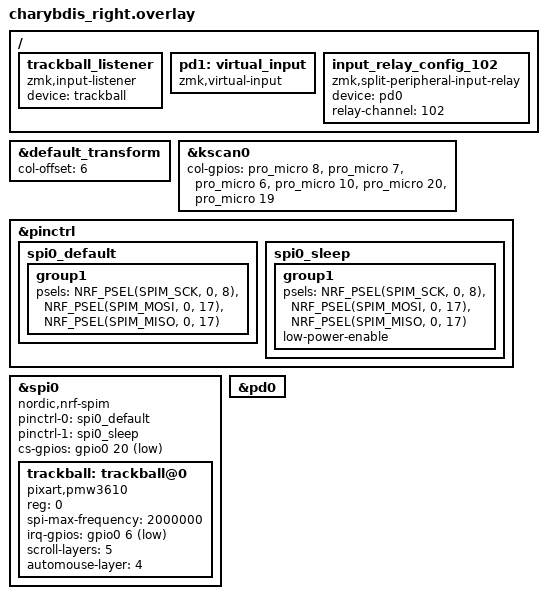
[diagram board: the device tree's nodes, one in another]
/*
 * Copyright (c) 2020 Ryan Cross
 *
 * SPDX-License-Identifier: MIT
 */

#include "charybdis.dtsi"

#define INPUT_EV_KEY 0x01               /**< Key event */
#define INPUT_EV_REL 0x02               /**< Relative coordinate event */
#define INPUT_EV_ABS 0x03               /**< Absolute coordinate event */
#define INPUT_EV_MSC 0x04               /**< Miscellaneous event */
#define INPUT_EV_VENDOR_START 0xf0      /**< Vendor specific event start */
#define INPUT_EV_VENDOR_STOP 0xff       /**< Vendor specific event stop */

#define INPUT_REL_X 0x00                /**< Relative X coordinate */
#define INPUT_REL_Y 0x01                /**< Relative Y coordinate */
#define INPUT_REL_WHEEL 0x08            /**< Relative wheel coordinate */
#define INPUT_REL_HWHEEL 0x06           /**< Relative horizontal wheel coordinate */
#define INPUT_REL_MISC 0x09             /**< Relative misc coordinate */

&default_transform {
    col-offset = <6>;
};

&kscan0 {
    col-gpios
        = <&pro_micro 8 (GPIO_ACTIVE_HIGH | GPIO_PULL_DOWN)>
        , <&pro_micro 7 (GPIO_ACTIVE_HIGH | GPIO_PULL_DOWN)>
        , <&pro_micro 6 (GPIO_ACTIVE_HIGH | GPIO_PULL_DOWN)>
        , <&pro_micro 10 (GPIO_ACTIVE_HIGH | GPIO_PULL_DOWN)>
        , <&pro_micro 20 (GPIO_ACTIVE_HIGH | GPIO_PULL_DOWN)>
        , <&pro_micro 19 (GPIO_ACTIVE_HIGH | GPIO_PULL_DOWN)>
        ;
};

&pinctrl {
    spi0_default: spi0_default {
        group1 {
            psels = <NRF_PSEL(SPIM_SCK, 0, 8)>,
                <NRF_PSEL(SPIM_MOSI, 0, 17)>,
                <NRF_PSEL(SPIM_MISO, 0, 17)>;
        };
    };

    spi0_sleep: spi0_sleep {
        group1 {
            psels = <NRF_PSEL(SPIM_SCK, 0, 8)>,
                <NRF_PSEL(SPIM_MOSI, 0, 17)>,
                <NRF_PSEL(SPIM_MISO, 0, 17)>;
            low-power-enable;
        };
    };
};

&spi0 {
    status = "okay";
    compatible = "nordic,nrf-spim";
    pinctrl-0 = <&spi0_default>;
    pinctrl-1 = <&spi0_sleep>;
    pinctrl-names = "default", "sleep";
    cs-gpios = <&gpio0 20 GPIO_ACTIVE_LOW>;

    trackball: trackball@0 {
        status = "okay";
        compatible = "pixart,pmw3610";
        reg = <0>;
        spi-max-frequency = <2000000>;
        irq-gpios = <&gpio0 6 (GPIO_ACTIVE_LOW | GPIO_PULL_UP)>;

        /*   optional features   */
        // snipe-layers = <1>;
        scroll-layers = <5>;
        automouse-layer = <4>;
    };
};

/ {
  trackball_listener {
    compatible = "zmk,input-listener";
    device = <&trackball>;

  };
};

/* enable &pd0 on split peripheral. typical input device for zephyr input subsystem. */
/* NOTE 1: use the same device alias (&pd0) on central and peripheral(s) is alright. */
/* NOTE 2: input event shall be intecepted by module `zmk-split-peripheral-input-relay`. */

/* this is an alias of your actual wired input device sensor in your peripheral shield. */
/* e.g. SPI optical sensor for trackball */
&pd0 {
	status = "okay";
	/* the rest of sensor config should be config here, e.g. gpios */
};

/ {
	/* THIS make keymap binding happy only, nothing happen on peripheral side */
	pd1: virtual_input {
		compatible = "zmk,virtual-input";
	};

	/* for peripheral side, define (input-device)-to-(relay-channel) mapping */
	input_relay_config_102 {
		compatible = "zmk,split-peripheral-input-relay";

		/* peripheral side input device, used to... */
		/*  - be intecepted on peripheral; */
		/*  - and then, be resurrected as `zmk,virtual-device` on central; */
		device = <&pd0>;
		
		/* channel id, used to be be transfered along with all input events. */
		/* NOTE 1: pick any 8bit integer. (1 - 255) */
		/* NOTE 2: should matching relay-channel on central overlay */
		relay-channel = <102>;
	};
};
